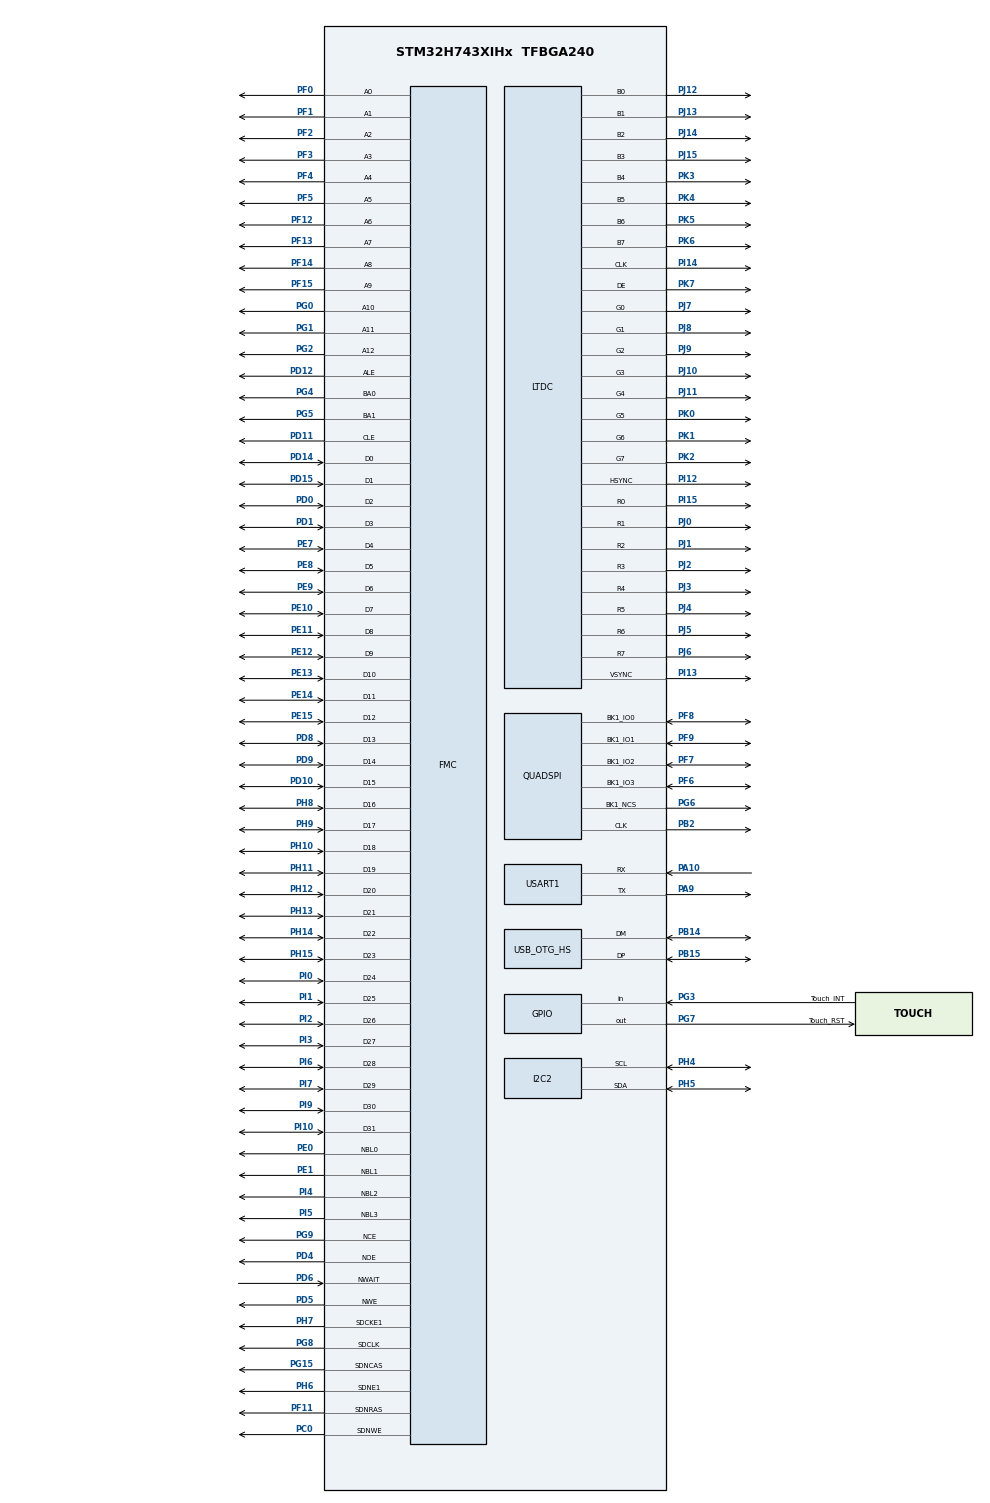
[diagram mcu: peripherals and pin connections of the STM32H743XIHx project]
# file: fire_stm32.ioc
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CORTEX_M7.AccessPermission-Cortex_Memory_Protection_Unit_Region1_Settings=MPU_REGION_PRIV_RW
CORTEX_M7.BaseAddress-Cortex_Memory_Protection_Unit_Region1_Settings=0xD0000000
CORTEX_M7.CPU_DCache=Enabled
CORTEX_M7.CPU_ICache=Enabled
CORTEX_M7.DisableExec-Cortex_Memory_Protection_Unit_Region0_Settings=MPU_INSTRUCTION_ACCESS_DISABLE
CORTEX_M7.DisableExec-Cortex_Memory_Protection_Unit_Region1_Settings=MPU_INSTRUCTION_ACCESS_ENABLE
CORTEX_M7.Enable-Cortex_Memory_Protection_Unit_Region0_Settings=MPU_REGION_ENABLE
CORTEX_M7.Enable-Cortex_Memory_Protection_Unit_Region1_Settings=MPU_REGION_ENABLE
CORTEX_M7.IsBufferable-Cortex_Memory_Protection_Unit_Region1_Settings=MPU_ACCESS_BUFFERABLE
CORTEX_M7.IsCacheable-Cortex_Memory_Protection_Unit_Region1_Settings=MPU_ACCESS_CACHEABLE
CORTEX_M7.IsShareable-Cortex_Memory_Protection_Unit_Region0_Settings=MPU_ACCESS_SHAREABLE
CORTEX_M7.IsShareable-Cortex_Memory_Protection_Unit_Region1_Settings=MPU_ACCESS_NOT_SHAREABLE
CORTEX_M7.AccessPermission-Cortex_Memory_Protection_Unit_Region2_Settings=MPU_REGION_FULL_ACCESS
CORTEX_M7.BaseAddress-Cortex_Memory_Protection_Unit_Region2_Settings=0x80000000
CORTEX_M7.DisableExec-Cortex_Memory_Protection_Unit_Region2_Settings=MPU_INSTRUCTION_ACCESS_DISABLE
CORTEX_M7.Enable-Cortex_Memory_Protection_Unit_Region2_Settings=MPU_REGION_ENABLE
CORTEX_M7.IsBufferable-Cortex_Memory_Protection_Unit_Region2_Settings=MPU_ACCESS_NOT_BUFFERABLE
CORTEX_M7.IsCacheable-Cortex_Memory_Protection_Unit_Region2_Settings=MPU_ACCESS_NOT_CACHEABLE
CORTEX_M7.IsShareable-Cortex_Memory_Protection_Unit_Region2_Settings=MPU_ACCESS_NOT_SHAREABLE
CORTEX_M7.Size-Cortex_Memory_Protection_Unit_Region2_Settings=MPU_REGION_SIZE_256MB
CORTEX_M7.SubRegionDisable-Cortex_Memory_Protection_Unit_Region2_Settings=0x00
CORTEX_M7.TypeExtField-Cortex_Memory_Protection_Unit_Region2_Settings=MPU_TEX_LEVEL0
CORTEX_M7.MPU_Control=MPU_PRIVILEGED_DEFAULT
CORTEX_M7.Size-Cortex_Memory_Protection_Unit_Region0_Settings=MPU_REGION_SIZE_4GB
CORTEX_M7.Size-Cortex_Memory_Protection_Unit_Region1_Settings=MPU_REGION_SIZE_64MB
CORTEX_M7.SubRegionDisable-Cortex_Memory_Protection_Unit_Region0_Settings=0x87
CORTEX_M7.TypeExtField-Cortex_Memory_Protection_Unit_Region1_Settings=MPU_TEX_LEVEL1
FMC.AttributeSpaceHiZSetupTime1=6
FMC.AttributeSpaceHoldSetupTime1=2
FMC.AttributeSpaceSetupTime1=2
FMC.AttributeSpaceWaitSetupTime1=6
FMC.CASLatency2=FMC_SDRAM_CAS_LATENCY_3
FMC.ColumnBitsNumber2=FMC_SDRAM_COLUMN_BITS_NUM_9
FMC.CommonSpaceHiZSetupTime1=6
FMC.CommonSpaceHoldSetupTime1=2
FMC.CommonSpaceSetupTime1=2
FMC.CommonSpaceWaitSetupTime1=6
FMC.EccComputation1=FMC_NAND_ECC_DISABLE
FMC.ExitSelfRefreshDelay2=8
FMC.LoadToActiveDelay2=2
FMC.NandBlockNbr1=1024
FMC.NandBlockSize1=64
FMC.NandExtraCommandEnable1=ENABLE
FMC.NandPageSize1=2048
FMC.NandPlaneNbr1=1
FMC.NandPlaneSize1=1024
FMC.NandSpareAreaSize1=64
FMC.RCDDelay2=2
FMC.RPDelay2=2
FMC.ReadBurst2=FMC_SDRAM_RBURST_ENABLE
FMC.ReadPipeDelay2=FMC_SDRAM_RPIPE_DELAY_1
FMC.RowBitsNumber2=FMC_SDRAM_ROW_BITS_NUM_13
FMC.RowCycleDelay2=8
FMC.SDBank2=FMC_SDRAM_BANK2
FMC.SDClockPeriod2=FMC_SDRAM_CLOCK_PERIOD_2
FMC.SelfRefreshTime2=5
FMC.TARSetupTime1=2
FMC.TCLRSetupTime1=2
FMC.WriteProtection2=FMC_SDRAM_WRITE_PROTECTION_DISABLE
FMC.WriteRecoveryTime2=4
FREERTOS.Tasks01=defaultTask,24,4096,StartDefaultTask,Default,NULL,Dynamic,NULL,NULL
FREERTOS.configENABLE_FPU=1
I2C2.Timing=0x90913232
LTDC.ActiveW=800
LTDC.HBP=46
LTDC.HFP=40
LTDC.HSync=1
LTDC.PCPolarity=LTDC_PCPOLARITY_IPC
LTDC.VBP=23
LTDC.VFP=13
LTDC.VSync=3
Mcu.Family=STM32H7
Mcu.Name=STM32H743XIHx
Mcu.Package=TFBGA240
NVIC.OTG_HS_IRQn=true\:5\:0\:false\:false\:true\:true\:true\:true\:true
NVIC.PriorityGroup=NVIC_PRIORITYGROUP_4
NVIC.TIM5_IRQn=true\:15\:0\:false\:false\:true\:false\:false\:true\:true
NVIC.TimeBase=TIM5_IRQn
NVIC.TimeBaseIP=TIM5
PA10.Mode=Asynchronous
PA10.Signal=USART1_RX
PA13\ (JTMS/SWDIO).Mode=Serial_Wire
PA13\ (JTMS/SWDIO).Signal=DEBUG_JTMS-SWDIO
PA14\ (JTCK/SWCLK).Mode=Serial_Wire
PA14\ (JTCK/SWCLK).Signal=DEBUG_JTCK-SWCLK
PA9.Mode=Asynchronous
PA9.Signal=USART1_TX
PB14.Mode=Device_Only_FS
PB14.Signal=USB_OTG_HS_DM
PB15.Mode=Device_Only_FS
PB15.Signal=USB_OTG_HS_DP
PB2.Mode=Single Bank 1
PB2.Signal=QUADSPI_CLK
PC0.Signal=FMC_SDNWE
PG3.GPIO_Label=Touch_INT
PG3.Signal=GPIO_Input
PG7.GPIO_Label=Touch_RST
PG7.GPIO_PinState=GPIO_PIN_RESET
PG7.GPIO_PuPd=GPIO_PULLDOWN
PG7.Signal=GPIO_Output
PD0.Signal=FMC_D2_DA2
PD1.Signal=FMC_D3_DA3
PD10.Signal=FMC_D15_DA15
PD11.Signal=FMC_A16_CLE
PD12.Signal=FMC_A17_ALE
PD14.Signal=FMC_D0_DA0
PD15.Signal=FMC_D1_DA1
PD4.Signal=FMC_NOE
PD5.Signal=FMC_NWE
PD6.Signal=FMC_NWAIT
PD8.Signal=FMC_D13_DA13
PD9.Signal=FMC_D14_DA14
PE0.Signal=FMC_NBL0
PE1.Signal=FMC_NBL1
PE10.Signal=FMC_D7_DA7
PE11.Signal=FMC_D8_DA8
PE12.Signal=FMC_D9_DA9
PE13.Signal=FMC_D10_DA10
PE14.Signal=FMC_D11_DA11
PE15.Signal=FMC_D12_DA12
PE7.Signal=FMC_D4_DA4
PE8.Signal=FMC_D5_DA5
PE9.Signal=FMC_D6_DA6
PF0.Signal=FMC_A0
PF1.Signal=FMC_A1
PF11.Signal=FMC_SDNRAS
PF12.Signal=FMC_A6
PF13.Signal=FMC_A7
PF14.Signal=FMC_A8
PF15.Signal=FMC_A9
PF2.Signal=FMC_A2
PF3.Signal=FMC_A3
PF4.Signal=FMC_A4
PF5.Signal=FMC_A5
PF6.Mode=Single Bank 1
PF6.Signal=QUADSPI_BK1_IO3
PF7.Mode=Single Bank 1
PF7.Signal=QUADSPI_BK1_IO2
PF8.Mode=Single Bank 1
PF8.Signal=QUADSPI_BK1_IO0
PF9.Mode=Single Bank 1
PF9.Signal=QUADSPI_BK1_IO1
PG0.Signal=FMC_A10
PG1.Signal=FMC_A11
PG15.Signal=FMC_SDNCAS
PG2.Signal=FMC_A12
PG4.Signal=FMC_A14_BA0
PG5.Signal=FMC_A15_BA1
PG6.Mode=Single Bank 1
PG6.Signal=QUADSPI_BK1_NCS
PG8.Signal=FMC_SDCLK
PG9.Mode=NandChipSelect3_1
PG9.Signal=FMC_NCE
PH0-OSC_IN\ (PH0).Mode=HSE-External-Oscillator
PH0-OSC_IN\ (PH0).Signal=RCC_OSC_IN
PH1-OSC_OUT\ (PH1).Mode=HSE-External-Oscillator
PH1-OSC_OUT\ (PH1).Signal=RCC_OSC_OUT
PH10.Signal=FMC_D18
PH4.Mode=I2C
PH4.Signal=I2C2_SCL
PH5.Mode=I2C
PH5.Signal=I2C2_SDA
PH11.Signal=FMC_D19
PH12.Signal=FMC_D20
PH13.Signal=FMC_D21
PH14.Signal=FMC_D22
PH15.Signal=FMC_D23
PH6.Mode=SdramChipSelect2_2
PH6.Signal=FMC_SDNE1
PH7.Mode=SdramChipSelect2_2
PH7.Signal=FMC_SDCKE1
PH8.Signal=FMC_D16
PH9.Signal=FMC_D17
PI0.Signal=FMC_D24
PI1.Signal=FMC_D25
PI10.Signal=FMC_D31
PI12.Mode=RGB888
PI12.Signal=LTDC_HSYNC
PI13.Mode=RGB888
PI13.Signal=LTDC_VSYNC
PI14.Mode=RGB888
PI14.Signal=LTDC_CLK
PI15.Mode=RGB888
PI15.Signal=LTDC_R0
PI2.Signal=FMC_D26
PI3.Signal=FMC_D27
PI4.Signal=FMC_NBL2
PI5.Signal=FMC_NBL3
PI6.Signal=FMC_D28
PI7.Signal=FMC_D29
PI9.Signal=FMC_D30
PJ0.Mode=RGB888
PJ0.Signal=LTDC_R1
PJ1.Mode=RGB888
PJ1.Signal=LTDC_R2
PJ10.Mode=RGB888
PJ10.Signal=LTDC_G3
PJ11.Mode=RGB888
PJ11.Signal=LTDC_G4
PJ12.Mode=RGB888
PJ12.Signal=LTDC_B0
PJ13.Mode=RGB888
PJ13.Signal=LTDC_B1
PJ14.Mode=RGB888
PJ14.Signal=LTDC_B2
PJ15.Mode=RGB888
PJ15.Signal=LTDC_B3
PJ2.Mode=RGB888
PJ2.Signal=LTDC_R3
PJ3.Mode=RGB888
PJ3.Signal=LTDC_R4
PJ4.Mode=RGB888
PJ4.Signal=LTDC_R5
PJ5.Mode=RGB888
PJ5.Signal=LTDC_R6
PJ6.Mode=RGB888
PJ6.Signal=LTDC_R7
PJ7.Mode=RGB888
PJ7.Signal=LTDC_G0
PJ8.Mode=RGB888
PJ8.Signal=LTDC_G1
PJ9.Mode=RGB888
PJ9.Signal=LTDC_G2
PK0.Mode=RGB888
PK0.Signal=LTDC_G5
PK1.Mode=RGB888
PK1.Signal=LTDC_G6
PK2.Mode=RGB888
PK2.Signal=LTDC_G7
PK3.Mode=RGB888
PK3.Signal=LTDC_B4
PK4.Mode=RGB888
PK4.Signal=LTDC_B5
PK5.Mode=RGB888
PK5.Signal=LTDC_B6
PK6.Mode=RGB888
PK6.Signal=LTDC_B7
PK7.Mode=RGB888
PK7.Signal=LTDC_DE
ProjectManager.HeapSize=0x200
ProjectManager.StackSize=0x400
ProjectManager.TargetToolchain=CMake
QUADSPI.ChipSelectHighTime=QSPI_CS_HIGH_TIME_5_CYCLE
QUADSPI.ClockMode=QSPI_CLOCK_MODE_0
QUADSPI.ClockPrescaler=1
QUADSPI.DualFlash=QSPI_DUALFLASH_DISABLE
QUADSPI.FifoThreshold=4
QUADSPI.FlashID=QSPI_FLASH_ID_1
QUADSPI.FlashSize=24
QUADSPI.SampleShifting=QSPI_SAMPLE_SHIFTING_HALFCYCLE
RCC.ADCFreq_Value=50390625
RCC.APB1Freq_Value=120000000
RCC.APB2Freq_Value=120000000
RCC.APB3Freq_Value=120000000
RCC.APB4Freq_Value=120000000
RCC.CortexFreq_Value=480000000
RCC.D1PPRE=RCC_APB3_DIV2
RCC.D2PPRE1=RCC_APB1_DIV2
RCC.D2PPRE2=RCC_APB2_DIV2
RCC.D3PPRE=RCC_APB4_DIV2
RCC.DIVM1=5
RCC.DIVM3=25
RCC.DIVN1=192
RCC.DIVN3=386
RCC.DIVQ1=20
RCC.DIVQ3=8
RCC.DIVR3=14
RCC.EnableCSSLSE=false
RCC.EnbaleCSS=true
RCC.HCLKFreq_Value=240000000
RCC.HPRE=RCC_HCLK_DIV2
RCC.LockedElements=USBoutput,CpuClockOutput
RCC.PLL3FRACN=5710
RCC.PLLFRACN=0
RCC.PLLSourceVirtual=RCC_PLLSOURCE_HSE
RCC.RTCClockSelection=RCC_RTCCLKSOURCE_LSI
RCC.SYSCLKFreq_VALUE=480000000
RCC.SYSCLKSource=RCC_SYSCLKSOURCE_PLLCLK
RCC.USBCLockSelection=RCC_USBCLKSOURCE_PLL
RCC.USBFreq_Value=48000000
SH.FMC_A0.0=FMC_A0,13b-sda2
SH.FMC_A1.0=FMC_A1,13b-sda2
SH.FMC_A10.0=FMC_A10,13b-sda2
SH.FMC_A11.0=FMC_A11,13b-sda2
SH.FMC_A12.0=FMC_A12,13b-sda2
SH.FMC_A14_BA0.0=FMC_BA0,FourSdramBanks2
SH.FMC_A15_BA1.0=FMC_BA1,FourSdramBanks2
SH.FMC_A16_CLE.0=FMC_CLE,8b-dmux1
SH.FMC_A17_ALE.0=FMC_ALE,8b-dmux1
SH.FMC_A2.0=FMC_A2,13b-sda2
SH.FMC_A3.0=FMC_A3,13b-sda2
SH.FMC_A4.0=FMC_A4,13b-sda2
SH.FMC_A5.0=FMC_A5,13b-sda2
SH.FMC_A6.0=FMC_A6,13b-sda2
SH.FMC_A7.0=FMC_A7,13b-sda2
SH.FMC_A8.0=FMC_A8,13b-sda2
SH.FMC_A9.0=FMC_A9,13b-sda2
SH.FMC_D0_DA0.0=FMC_D0,sd-32b-d2
SH.FMC_D0_DA0.1=FMC_D0,8b-dmux1
SH.FMC_D10_DA10.0=FMC_D10,sd-32b-d2
SH.FMC_D11_DA11.0=FMC_D11,sd-32b-d2
SH.FMC_D12_DA12.0=FMC_D12,sd-32b-d2
SH.FMC_D13_DA13.0=FMC_D13,sd-32b-d2
SH.FMC_D14_DA14.0=FMC_D14,sd-32b-d2
SH.FMC_D15_DA15.0=FMC_D15,sd-32b-d2
SH.FMC_D16.0=FMC_D16,sd-32b-d2
SH.FMC_D17.0=FMC_D17,sd-32b-d2
SH.FMC_D18.0=FMC_D18,sd-32b-d2
SH.FMC_D19.0=FMC_D19,sd-32b-d2
SH.FMC_D1_DA1.0=FMC_D1,sd-32b-d2
SH.FMC_D1_DA1.1=FMC_D1,8b-dmux1
SH.FMC_D20.0=FMC_D20,sd-32b-d2
SH.FMC_D21.0=FMC_D21,sd-32b-d2
SH.FMC_D22.0=FMC_D22,sd-32b-d2
SH.FMC_D23.0=FMC_D23,sd-32b-d2
SH.FMC_D24.0=FMC_D24,sd-32b-d2
SH.FMC_D25.0=FMC_D25,sd-32b-d2
SH.FMC_D26.0=FMC_D26,sd-32b-d2
SH.FMC_D27.0=FMC_D27,sd-32b-d2
SH.FMC_D28.0=FMC_D28,sd-32b-d2
SH.FMC_D29.0=FMC_D29,sd-32b-d2
SH.FMC_D2_DA2.0=FMC_D2,sd-32b-d2
SH.FMC_D2_DA2.1=FMC_D2,8b-dmux1
SH.FMC_D30.0=FMC_D30,sd-32b-d2
SH.FMC_D31.0=FMC_D31,sd-32b-d2
SH.FMC_D3_DA3.0=FMC_D3,sd-32b-d2
SH.FMC_D3_DA3.1=FMC_D3,8b-dmux1
SH.FMC_D4_DA4.0=FMC_D4,sd-32b-d2
SH.FMC_D4_DA4.1=FMC_D4,8b-dmux1
SH.FMC_D5_DA5.0=FMC_D5,sd-32b-d2
SH.FMC_D5_DA5.1=FMC_D5,8b-dmux1
SH.FMC_D6_DA6.0=FMC_D6,sd-32b-d2
SH.FMC_D6_DA6.1=FMC_D6,8b-dmux1
SH.FMC_D7_DA7.0=FMC_D7,sd-32b-d2
SH.FMC_D7_DA7.1=FMC_D7,8b-dmux1
SH.FMC_D8_DA8.0=FMC_D8,sd-32b-d2
SH.FMC_D9_DA9.0=FMC_D9,sd-32b-d2
SH.FMC_NBL0.0=FMC_NBL0,Sd4ByteEnable2
SH.FMC_NBL1.0=FMC_NBL1,Sd4ByteEnable2
SH.FMC_NBL2.0=FMC_NBL2,Sd4ByteEnable2
SH.FMC_NBL3.0=FMC_NBL3,Sd4ByteEnable2
SH.FMC_NOE.0=FMC_NOE,8b-dmux1
SH.FMC_NWAIT.0=FMC_NWAIT,Wait1
SH.FMC_NWE.0=FMC_NWE,8b-dmux1
SH.FMC_SDCLK.0=FMC_SDCLK,13b-sda2
SH.FMC_SDNCAS.0=FMC_SDNCAS,13b-sda2
SH.FMC_SDNRAS.0=FMC_SDNRAS,13b-sda2
SH.FMC_SDNWE.0=FMC_SDNWE,13b-sda2
USART1.VirtualMode-Asynchronous=VM_ASYNC
USB_OTG_HS.VirtualMode-Device_Only_FS=Device_Only_FS
VP_DMA2D_VS_DMA2D.Mode=DMA2D_Activate
VP_FREERTOS_VS_CMSIS_V2.Mode=CMSIS_V2
VP_LIBJPEG_VS_JPEGLIB.Mode=Enabled
VP_MEMORYMAP_VS_MEMORYMAP.Mode=CurAppReg
VP_RNG_VS_RNG.Mode=RNG_Activate
VP_RTC_VS_RTC_Activate.Mode=RTC_Enabled
VP_SYS_VS_tim5.Mode=TIM5
board=custom

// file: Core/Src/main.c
/* USER CODE BEGIN Header */
/**
  ******************************************************************************
  * @file           : main.c
  * @brief          : Main program body
  ******************************************************************************
  * @attention
  *
  * Copyright (c) 2026 STMicroelectronics.
  * All rights reserved.
  *
  * This software is licensed under terms that can be found in the LICENSE file
  * in the root directory of this software component.
  * If no LICENSE file comes with this software, it is provided AS-IS.
  *
  ******************************************************************************
  */
/* USER CODE END Header */
#include "main.h"
#include "FreeRTOS.h"
#include "cmsis_os2.h"
#include "libjpeg.h"

/* USER CODE BEGIN Includes */
#include "lvgl.h"
#include "lvgl/drivers/display/lv_st_ltdc.h"
#include "demos/lv_demos.h"
#include "yaffs_osglue.h"
#include "touch.h"
#include "task.h"
/* USER CODE END Includes */

/* USER CODE BEGIN PD */
/* Framebuffers in SDRAM, RGB565 800x480 */
#define FB_ADDR1  0xD0000000
#define FB_ADDR2  (FB_ADDR1 + 800 * 480 * 2)
/* USER CODE END PD */

DMA2D_HandleTypeDef hdma2d;

I2C_HandleTypeDef hi2c2;

LTDC_HandleTypeDef hltdc;

QSPI_HandleTypeDef hqspi;

RNG_HandleTypeDef hrng;

RTC_HandleTypeDef hrtc;

UART_HandleTypeDef huart1;

PCD_HandleTypeDef hpcd_USB_OTG_HS;

NAND_HandleTypeDef hnand1;
SDRAM_HandleTypeDef hsdram2;

/* Definitions for defaultTask */
osThreadId_t defaultTaskHandle;
const osThreadAttr_t defaultTask_attributes = {
  .name = "defaultTask",
  .stack_size = 6144 * 4,
  .priority = (osPriority_t) osPriorityNormal,
};
/* USER CODE BEGIN PV */
/* FreeRTOS heap must live in RAM_D2 (DTCMRAM is too small); heap_4 does not
   require zero-initialized memory, so a NOLOAD custom section is fine. */
__attribute__((section(".ram_d2_heap")))
uint8_t ucHeap[configTOTAL_HEAP_SIZE];

osThreadId_t mountTaskHandle;
const osThreadAttr_t mountTask_attributes = {
  .name = "mountTask",
  .stack_size = 2048 * 4,
  .priority = (osPriority_t) osPriorityBelowNormal,
};
/* USER CODE END PV */

void SystemClock_Config(void);
void PeriphCommonClock_Config(void);
static void MPU_Config(void);
static void MX_GPIO_Init(void);
static void MX_FMC_Init(void);
static void MX_QUADSPI_Init(void);
static void MX_USART1_UART_Init(void);
static void MX_I2C2_Init(void);
static void MX_DMA2D_Init(void);
static void MX_RNG_Init(void);
static void MX_RTC_Init(void);
static void MX_USB_OTG_HS_PCD_Init(void);
static void MX_LTDC_Init(void);
void StartDefaultTask(void *argument);

/* USER CODE BEGIN PFP */
void StartMountTask(void *argument);
/* USER CODE END PFP */

int main(void)
{

  /* USER CODE BEGIN 1 */
  /* FMC NAND mapped at 0x80000000 must be Device/non-cacheable. Configured
     here instead of inside MPU_Config() because CubeMX regenerates that whole
     function; region registers persist, so MPU_Config() re-enabling the MPU
     keeps this setting. */
  {
    MPU_Region_InitTypeDef nand_region = {0};
    HAL_MPU_Disable();
    nand_region.Enable = MPU_REGION_ENABLE;
    nand_region.Number = MPU_REGION_NUMBER2;
    nand_region.BaseAddress = 0x80000000;
    nand_region.Size = MPU_REGION_SIZE_256MB;
    nand_region.SubRegionDisable = 0x00;
    nand_region.TypeExtField = MPU_TEX_LEVEL0;
    nand_region.AccessPermission = MPU_REGION_FULL_ACCESS;
    nand_region.DisableExec = MPU_INSTRUCTION_ACCESS_DISABLE;
    nand_region.IsShareable = MPU_ACCESS_NOT_SHAREABLE;
    nand_region.IsCacheable = MPU_ACCESS_NOT_CACHEABLE;
    nand_region.IsBufferable = MPU_ACCESS_NOT_BUFFERABLE;
    HAL_MPU_ConfigRegion(&nand_region);
  }
  /* USER CODE END 1 */

  /* MPU Configuration--------------------------------------------------------*/
  MPU_Config();

  /* Enable the CPU Cache */

  /* Enable I-Cache---------------------------------------------------------*/
  SCB_EnableICache();

  /* Enable D-Cache---------------------------------------------------------*/
  SCB_EnableDCache();

  /* MCU Configuration--------------------------------------------------------*/

  /* Reset of all peripherals, Initializes the Flash interface and the Systick. */
  HAL_Init();

  /* Configure the system clock */
  SystemClock_Config();

  /* Configure the peripherals common clocks */
  PeriphCommonClock_Config();

  /* USER CODE BEGIN SysInit */
  /* RAM_D2 hosts the FreeRTOS heap (.ram_d2_heap) */
  __HAL_RCC_D2SRAM1_CLK_ENABLE();
  __HAL_RCC_D2SRAM2_CLK_ENABLE();
  __HAL_RCC_D2SRAM3_CLK_ENABLE();
  /* USER CODE END SysInit */

  /* Initialize all configured peripherals */
  MX_GPIO_Init();
  MX_FMC_Init();
  MX_QUADSPI_Init();
  MX_USART1_UART_Init();
  MX_I2C2_Init();
  MX_DMA2D_Init();
  MX_RNG_Init();
  MX_RTC_Init();
  MX_LIBJPEG_Init();
  MX_USB_OTG_HS_PCD_Init();
  MX_LTDC_Init();
  /* USER CODE BEGIN 2 */
  /* LCD backlight: PD13, stays OFF until the first LVGL frame is rendered */
  __HAL_RCC_GPIOD_CLK_ENABLE();
  GPIO_InitTypeDef gpio = {0};
  gpio.Pin = GPIO_PIN_13;
  gpio.Mode = GPIO_MODE_OUTPUT_PP;
  gpio.Pull = GPIO_NOPULL;
  gpio.Speed = GPIO_SPEED_FREQ_LOW;
  HAL_GPIO_Init(GPIOD, &gpio);
  HAL_GPIO_WritePin(GPIOD, GPIO_PIN_13, GPIO_PIN_RESET);
  /* USER CODE END 2 */

  /* Init scheduler */
  osKernelInitialize();

  /* Create the thread(s) */
  /* creation of defaultTask */
  defaultTaskHandle = osThreadNew(StartDefaultTask, NULL, &defaultTask_attributes);

  /* USER CODE BEGIN RTOS_THREADS */
  mountTaskHandle = osThreadNew(StartMountTask, NULL, &mountTask_attributes);
  /* USER CODE END RTOS_THREADS */

  /* Start scheduler */
  osKernelStart();

  /* We should never get here as control is now taken by the scheduler */

  /* Infinite loop */
  while (1)
  {

  }
}

void SystemClock_Config(void)
{
  RCC_OscInitTypeDef RCC_OscInitStruct = {0};
  RCC_ClkInitTypeDef RCC_ClkInitStruct = {0};

  /** Supply configuration update enable
  */
  HAL_PWREx_ConfigSupply(PWR_LDO_SUPPLY);

  /** Configure the main internal regulator output voltage
  */
  __HAL_PWR_VOLTAGESCALING_CONFIG(PWR_REGULATOR_VOLTAGE_SCALE0);

  while(!__HAL_PWR_GET_FLAG(PWR_FLAG_VOSRDY)) {}

  /* RTC runs from LSI: no 32.768kHz crystal is fitted on this board, and
     waiting on LSE here would fail into Error_Handler() before any display
     init runs. */
  HAL_PWR_EnableBkUpAccess();

  /** Initializes the RCC Oscillators according to the specified parameters
  * in the RCC_OscInitTypeDef structure.
  */
  RCC_OscInitStruct.OscillatorType = RCC_OSCILLATORTYPE_HSI48|RCC_OSCILLATORTYPE_LSI
                              |RCC_OSCILLATORTYPE_HSE;
  RCC_OscInitStruct.HSEState = RCC_HSE_ON;
  RCC_OscInitStruct.LSIState = RCC_LSI_ON;
  RCC_OscInitStruct.HSI48State = RCC_HSI48_ON;
  RCC_OscInitStruct.PLL.PLLState = RCC_PLL_ON;
  RCC_OscInitStruct.PLL.PLLSource = RCC_PLLSOURCE_HSE;
  RCC_OscInitStruct.PLL.PLLM = 5;
  RCC_OscInitStruct.PLL.PLLN = 192;
  RCC_OscInitStruct.PLL.PLLP = 2;
  RCC_OscInitStruct.PLL.PLLQ = 20;
  RCC_OscInitStruct.PLL.PLLR = 2;
  RCC_OscInitStruct.PLL.PLLRGE = RCC_PLL1VCIRANGE_2;
  RCC_OscInitStruct.PLL.PLLVCOSEL = RCC_PLL1VCOWIDE;
  RCC_OscInitStruct.PLL.PLLFRACN = 0;
  if (HAL_RCC_OscConfig(&RCC_OscInitStruct) != HAL_OK)
  {
    Error_Handler();
  }

  /** Initializes the CPU, AHB and APB buses clocks
  */
  RCC_ClkInitStruct.ClockType = RCC_CLOCKTYPE_HCLK|RCC_CLOCKTYPE_SYSCLK
                              |RCC_CLOCKTYPE_PCLK1|RCC_CLOCKTYPE_PCLK2
                              |RCC_CLOCKTYPE_D3PCLK1|RCC_CLOCKTYPE_D1PCLK1;
  RCC_ClkInitStruct.SYSCLKSource = RCC_SYSCLKSOURCE_PLLCLK;
  RCC_ClkInitStruct.SYSCLKDivider = RCC_SYSCLK_DIV1;
  RCC_ClkInitStruct.AHBCLKDivider = RCC_HCLK_DIV2;
  RCC_ClkInitStruct.APB3CLKDivider = RCC_APB3_DIV2;
  RCC_ClkInitStruct.APB1CLKDivider = RCC_APB1_DIV2;
  RCC_ClkInitStruct.APB2CLKDivider = RCC_APB2_DIV2;
  RCC_ClkInitStruct.APB4CLKDivider = RCC_APB4_DIV2;

  if (HAL_RCC_ClockConfig(&RCC_ClkInitStruct, FLASH_LATENCY_4) != HAL_OK)
  {
    Error_Handler();
  }

  /** Enables the Clock Security System
  */
  HAL_RCC_EnableCSS();
}

void PeriphCommonClock_Config(void)
{
  RCC_PeriphCLKInitTypeDef PeriphClkInitStruct = {0};

  /** Initializes the peripherals clock
  */
  PeriphClkInitStruct.PeriphClockSelection = RCC_PERIPHCLK_USB|RCC_PERIPHCLK_LTDC;
  /* LTDC pixel clock for 60Hz: (386 + 5710/8192)MHz / 14 = 27.6212MHz;
     27.6212MHz / (887 * 519) = 60.00Hz */
  PeriphClkInitStruct.PLL3.PLL3M = 25;
  PeriphClkInitStruct.PLL3.PLL3N = 386;
  PeriphClkInitStruct.PLL3.PLL3P = 2;
  PeriphClkInitStruct.PLL3.PLL3Q = 8;
  PeriphClkInitStruct.PLL3.PLL3R = 14;
  PeriphClkInitStruct.PLL3.PLL3RGE = RCC_PLL3VCIRANGE_0;
  PeriphClkInitStruct.PLL3.PLL3VCOSEL = RCC_PLL3VCOWIDE;
  PeriphClkInitStruct.PLL3.PLL3FRACN = 5710;
  /* USB now from PLL1Q (48MHz exact); PLL3 VCO is no longer 384MHz */
  PeriphClkInitStruct.UsbClockSelection = RCC_USBCLKSOURCE_PLL;
  if (HAL_RCCEx_PeriphCLKConfig(&PeriphClkInitStruct) != HAL_OK)
  {
    Error_Handler();
  }
}

static void MX_DMA2D_Init(void)
{

  hdma2d.Instance = DMA2D;
  hdma2d.Init.Mode = DMA2D_M2M;
  hdma2d.Init.ColorMode = DMA2D_OUTPUT_ARGB8888;
  hdma2d.Init.OutputOffset = 0;
  hdma2d.LayerCfg[1].InputOffset = 0;
  hdma2d.LayerCfg[1].InputColorMode = DMA2D_INPUT_ARGB8888;
  hdma2d.LayerCfg[1].AlphaMode = DMA2D_NO_MODIF_ALPHA;
  hdma2d.LayerCfg[1].InputAlpha = 0;
  hdma2d.LayerCfg[1].AlphaInverted = DMA2D_REGULAR_ALPHA;
  hdma2d.LayerCfg[1].RedBlueSwap = DMA2D_RB_REGULAR;
  hdma2d.LayerCfg[1].ChromaSubSampling = DMA2D_NO_CSS;
  if (HAL_DMA2D_Init(&hdma2d) != HAL_OK)
  {
    Error_Handler();
  }
  if (HAL_DMA2D_ConfigLayer(&hdma2d, 1) != HAL_OK)
  {
    Error_Handler();
  }
  /* USER CODE BEGIN DMA2D_Init 2 */
  HAL_NVIC_SetPriority(DMA2D_IRQn, 6, 0);
  HAL_NVIC_EnableIRQ(DMA2D_IRQn);
  /* USER CODE END DMA2D_Init 2 */

}

static void MX_I2C2_Init(void)
{

  hi2c2.Instance = I2C2;
  hi2c2.Init.Timing = 0x90913232;
  hi2c2.Init.OwnAddress1 = 0;
  hi2c2.Init.AddressingMode = I2C_ADDRESSINGMODE_7BIT;
  hi2c2.Init.DualAddressMode = I2C_DUALADDRESS_DISABLE;
  hi2c2.Init.OwnAddress2 = 0;
  hi2c2.Init.OwnAddress2Masks = I2C_OA2_NOMASK;
  hi2c2.Init.GeneralCallMode = I2C_GENERALCALL_DISABLE;
  hi2c2.Init.NoStretchMode = I2C_NOSTRETCH_DISABLE;
  if (HAL_I2C_Init(&hi2c2) != HAL_OK)
  {
    Error_Handler();
  }

  /** Configure Analogue filter
  */
  if (HAL_I2CEx_ConfigAnalogFilter(&hi2c2, I2C_ANALOGFILTER_ENABLE) != HAL_OK)
  {
    Error_Handler();
  }

  /** Configure Digital filter
  */
  if (HAL_I2CEx_ConfigDigitalFilter(&hi2c2, 0) != HAL_OK)
  {
    Error_Handler();
  }

}

static void MX_LTDC_Init(void)
{

  LTDC_LayerCfgTypeDef pLayerCfg = {0};
  LTDC_LayerCfgTypeDef pLayerCfg1 = {0};

  hltdc.Instance = LTDC;
  hltdc.Init.HSPolarity = LTDC_HSPOLARITY_AL;
  hltdc.Init.VSPolarity = LTDC_VSPOLARITY_AL;
  hltdc.Init.DEPolarity = LTDC_DEPOLARITY_AL;
  hltdc.Init.PCPolarity = LTDC_PCPOLARITY_IPC;
  hltdc.Init.HorizontalSync = 0;
  hltdc.Init.VerticalSync = 2;
  hltdc.Init.AccumulatedHBP = 46;
  hltdc.Init.AccumulatedVBP = 25;
  hltdc.Init.AccumulatedActiveW = 846;
  hltdc.Init.AccumulatedActiveH = 505;
  hltdc.Init.TotalWidth = 886;
  hltdc.Init.TotalHeigh = 518;
  hltdc.Init.Backcolor.Blue = 0;
  hltdc.Init.Backcolor.Green = 0;
  hltdc.Init.Backcolor.Red = 0;
  if (HAL_LTDC_Init(&hltdc) != HAL_OK)
  {
    Error_Handler();
  }
  pLayerCfg.WindowX0 = 0;
  pLayerCfg.WindowX1 = 0;
  pLayerCfg.WindowY0 = 0;
  pLayerCfg.WindowY1 = 0;
  pLayerCfg.PixelFormat = LTDC_PIXEL_FORMAT_ARGB8888;
  pLayerCfg.Alpha = 0;
  pLayerCfg.Alpha0 = 0;
  pLayerCfg.BlendingFactor1 = LTDC_BLENDING_FACTOR1_CA;
  pLayerCfg.BlendingFactor2 = LTDC_BLENDING_FACTOR2_CA;
  pLayerCfg.FBStartAdress = 0;
  pLayerCfg.ImageWidth = 0;
  pLayerCfg.ImageHeight = 0;
  pLayerCfg.Backcolor.Blue = 0;
  pLayerCfg.Backcolor.Green = 0;
  pLayerCfg.Backcolor.Red = 0;
  if (HAL_LTDC_ConfigLayer(&hltdc, &pLayerCfg, 0) != HAL_OK)
  {
    Error_Handler();
  }
  pLayerCfg1.WindowX0 = 0;
  pLayerCfg1.WindowX1 = 0;
  pLayerCfg1.WindowY0 = 0;
  pLayerCfg1.WindowY1 = 0;
  pLayerCfg1.PixelFormat = LTDC_PIXEL_FORMAT_ARGB8888;
  pLayerCfg1.Alpha = 0;
  pLayerCfg1.Alpha0 = 0;
  pLayerCfg1.BlendingFactor1 = LTDC_BLENDING_FACTOR1_CA;
  pLayerCfg1.BlendingFactor2 = LTDC_BLENDING_FACTOR2_CA;
  pLayerCfg1.FBStartAdress = 0;
  pLayerCfg1.ImageWidth = 0;
  pLayerCfg1.ImageHeight = 0;
  pLayerCfg1.Backcolor.Blue = 0;
  pLayerCfg1.Backcolor.Green = 0;
  pLayerCfg1.Backcolor.Red = 0;
  if (HAL_LTDC_ConfigLayer(&hltdc, &pLayerCfg1, 1) != HAL_OK)
  {
    Error_Handler();
  }
  /* USER CODE BEGIN LTDC_Init 2 */
  /* Configure layer 0 for LVGL: 800x480 RGB565, framebuffer in SDRAM */
  hltdc.LayerCfg[0].WindowX0 = 0;
  hltdc.LayerCfg[0].WindowX1 = 800;
  hltdc.LayerCfg[0].WindowY0 = 0;
  hltdc.LayerCfg[0].WindowY1 = 480;
  hltdc.LayerCfg[0].PixelFormat = LTDC_PIXEL_FORMAT_RGB565;
  hltdc.LayerCfg[0].Alpha = 255;
  hltdc.LayerCfg[0].FBStartAdress = 0xD0000000;
  hltdc.LayerCfg[0].ImageWidth = 800;
  hltdc.LayerCfg[0].ImageHeight = 480;
  HAL_LTDC_ConfigLayer(&hltdc, &hltdc.LayerCfg[0], 0);
  /* The LVGL LTDC driver uses the register-reload interrupt to sync
     framebuffer swaps. Priority 6 is at or below the FreeRTOS max-syscall
     priority (5), which the ISR callbacks require. */
  HAL_NVIC_SetPriority(LTDC_IRQn, 6, 0);
  HAL_NVIC_EnableIRQ(LTDC_IRQn);
  /* USER CODE END LTDC_Init 2 */

}

static void MX_QUADSPI_Init(void)
{

  /* QUADSPI parameter configuration*/
  hqspi.Instance = QUADSPI;
  hqspi.Init.ClockPrescaler = 1;
  hqspi.Init.FifoThreshold = 4;
  hqspi.Init.SampleShifting = QSPI_SAMPLE_SHIFTING_HALFCYCLE;
  hqspi.Init.FlashSize = 24;
  hqspi.Init.ChipSelectHighTime = QSPI_CS_HIGH_TIME_5_CYCLE;
  hqspi.Init.ClockMode = QSPI_CLOCK_MODE_0;
  hqspi.Init.FlashID = QSPI_FLASH_ID_1;
  hqspi.Init.DualFlash = QSPI_DUALFLASH_DISABLE;
  if (HAL_QSPI_Init(&hqspi) != HAL_OK)
  {
    Error_Handler();
  }

}

static void MX_RNG_Init(void)
{

  hrng.Instance = RNG;
  hrng.Init.ClockErrorDetection = RNG_CED_ENABLE;
  if (HAL_RNG_Init(&hrng) != HAL_OK)
  {
    Error_Handler();
  }

}

static void MX_RTC_Init(void)
{

  /** Initialize RTC Only
  */
  hrtc.Instance = RTC;
  hrtc.Init.HourFormat = RTC_HOURFORMAT_24;
  hrtc.Init.AsynchPrediv = 127;
  hrtc.Init.SynchPrediv = 249;
  hrtc.Init.OutPut = RTC_OUTPUT_DISABLE;
  hrtc.Init.OutPutPolarity = RTC_OUTPUT_POLARITY_HIGH;
  hrtc.Init.OutPutType = RTC_OUTPUT_TYPE_OPENDRAIN;
  hrtc.Init.OutPutRemap = RTC_OUTPUT_REMAP_NONE;
  if (HAL_RTC_Init(&hrtc) != HAL_OK)
  {
    Error_Handler();
  }

}

static void MX_USART1_UART_Init(void)
{

  huart1.Instance = USART1;
  huart1.Init.BaudRate = 115200;
  huart1.Init.WordLength = UART_WORDLENGTH_8B;
  huart1.Init.StopBits = UART_STOPBITS_1;
  huart1.Init.Parity = UART_PARITY_NONE;
  huart1.Init.Mode = UART_MODE_TX_RX;
  huart1.Init.HwFlowCtl = UART_HWCONTROL_NONE;
  huart1.Init.OverSampling = UART_OVERSAMPLING_16;
  huart1.Init.OneBitSampling = UART_ONE_BIT_SAMPLE_DISABLE;
  huart1.Init.ClockPrescaler = UART_PRESCALER_DIV1;
  huart1.AdvancedInit.AdvFeatureInit = UART_ADVFEATURE_NO_INIT;
  if (HAL_UART_Init(&huart1) != HAL_OK)
  {
    Error_Handler();
  }
  if (HAL_UARTEx_SetTxFifoThreshold(&huart1, UART_TXFIFO_THRESHOLD_1_8) != HAL_OK)
  {
    Error_Handler();
  }
  if (HAL_UARTEx_SetRxFifoThreshold(&huart1, UART_RXFIFO_THRESHOLD_1_8) != HAL_OK)
  {
    Error_Handler();
  }
  if (HAL_UARTEx_DisableFifoMode(&huart1) != HAL_OK)
  {
    Error_Handler();
  }

}

static void MX_USB_OTG_HS_PCD_Init(void)
{

  hpcd_USB_OTG_HS.Instance = USB_OTG_HS;
  hpcd_USB_OTG_HS.Init.dev_endpoints = 9;
  hpcd_USB_OTG_HS.Init.speed = PCD_SPEED_FULL;
  hpcd_USB_OTG_HS.Init.dma_enable = DISABLE;
  hpcd_USB_OTG_HS.Init.phy_itface = USB_OTG_EMBEDDED_PHY;
  hpcd_USB_OTG_HS.Init.Sof_enable = DISABLE;
  hpcd_USB_OTG_HS.Init.low_power_enable = DISABLE;
  hpcd_USB_OTG_HS.Init.lpm_enable = DISABLE;
  hpcd_USB_OTG_HS.Init.vbus_sensing_enable = DISABLE;
  hpcd_USB_OTG_HS.Init.use_dedicated_ep1 = DISABLE;
  hpcd_USB_OTG_HS.Init.use_external_vbus = DISABLE;
  if (HAL_PCD_Init(&hpcd_USB_OTG_HS) != HAL_OK)
  {
    Error_Handler();
  }

}

/* FMC initialization function */
static void MX_FMC_Init(void)
{

  FMC_NAND_PCC_TimingTypeDef ComSpaceTiming = {0};
  FMC_NAND_PCC_TimingTypeDef AttSpaceTiming = {0};
  FMC_SDRAM_TimingTypeDef SdramTiming = {0};

  /** Perform the NAND1 memory initialization sequence
  */
  hnand1.Instance = FMC_NAND_DEVICE;
  /* hnand1.Init */
  hnand1.Init.NandBank = FMC_NAND_BANK3;
  hnand1.Init.Waitfeature = FMC_NAND_WAIT_FEATURE_ENABLE;
  hnand1.Init.MemoryDataWidth = FMC_NAND_MEM_BUS_WIDTH_8;
  hnand1.Init.EccComputation = FMC_NAND_ECC_DISABLE;
  hnand1.Init.ECCPageSize = FMC_NAND_ECC_PAGE_SIZE_256BYTE;
  hnand1.Init.TCLRSetupTime = 2;
  hnand1.Init.TARSetupTime = 2;
  /* hnand1.Config */
  hnand1.Config.PageSize = 2048;
  hnand1.Config.SpareAreaSize = 64;
  hnand1.Config.BlockSize = 64;
  hnand1.Config.BlockNbr = 1024;
  hnand1.Config.PlaneNbr = 1;
  hnand1.Config.PlaneSize = 1024;
  hnand1.Config.ExtraCommandEnable = ENABLE;
  /* ComSpaceTiming */
  ComSpaceTiming.SetupTime = 2;
  ComSpaceTiming.WaitSetupTime = 6;
  ComSpaceTiming.HoldSetupTime = 2;
  ComSpaceTiming.HiZSetupTime = 6;
  /* AttSpaceTiming */
  AttSpaceTiming.SetupTime = 2;
  AttSpaceTiming.WaitSetupTime = 6;
  AttSpaceTiming.HoldSetupTime = 2;
  AttSpaceTiming.HiZSetupTime = 6;

  if (HAL_NAND_Init(&hnand1, &ComSpaceTiming, &AttSpaceTiming) != HAL_OK)
  {
    Error_Handler( );
  }

  /** Perform the SDRAM2 memory initialization sequence
  */
  hsdram2.Instance = FMC_SDRAM_DEVICE;
  /* hsdram2.Init */
  hsdram2.Init.SDBank = FMC_SDRAM_BANK2;
  hsdram2.Init.ColumnBitsNumber = FMC_SDRAM_COLUMN_BITS_NUM_9;
  hsdram2.Init.RowBitsNumber = FMC_SDRAM_ROW_BITS_NUM_13;
  hsdram2.Init.MemoryDataWidth = FMC_SDRAM_MEM_BUS_WIDTH_32;
  hsdram2.Init.InternalBankNumber = FMC_SDRAM_INTERN_BANKS_NUM_4;
  hsdram2.Init.CASLatency = FMC_SDRAM_CAS_LATENCY_3;
  hsdram2.Init.WriteProtection = FMC_SDRAM_WRITE_PROTECTION_DISABLE;
  hsdram2.Init.SDClockPeriod = FMC_SDRAM_CLOCK_PERIOD_2;
  hsdram2.Init.ReadBurst = FMC_SDRAM_RBURST_ENABLE;
  hsdram2.Init.ReadPipeDelay = FMC_SDRAM_RPIPE_DELAY_1;
  /* SdramTiming */
  SdramTiming.LoadToActiveDelay = 2;
  SdramTiming.ExitSelfRefreshDelay = 8;
  SdramTiming.SelfRefreshTime = 5;
  SdramTiming.RowCycleDelay = 8;
  SdramTiming.WriteRecoveryTime = 4;
  SdramTiming.RPDelay = 2;
  SdramTiming.RCDDelay = 2;

  if (HAL_SDRAM_Init(&hsdram2, &SdramTiming) != HAL_OK)
  {
    Error_Handler( );
  }

  /* USER CODE BEGIN FMC_Init 2 */

  /* SDRAM initialization command sequence */
  FMC_SDRAM_CommandTypeDef cmd = {0};

  cmd.CommandMode  = FMC_SDRAM_CMD_CLK_ENABLE;
  cmd.CommandTarget = FMC_SDRAM_CMD_TARGET_BANK2;
  HAL_SDRAM_SendCommand(&hsdram2, &cmd, 0xFFFF);
  HAL_Delay(1);

  cmd.CommandMode  = FMC_SDRAM_CMD_PALL;
  cmd.CommandTarget = FMC_SDRAM_CMD_TARGET_BANK2;
  HAL_SDRAM_SendCommand(&hsdram2, &cmd, 0xFFFF);

  cmd.CommandMode     = FMC_SDRAM_CMD_AUTOREFRESH_MODE;
  cmd.CommandTarget   = FMC_SDRAM_CMD_TARGET_BANK2;
  cmd.AutoRefreshNumber = 8;
  HAL_SDRAM_SendCommand(&hsdram2, &cmd, 0xFFFF);

  cmd.CommandMode  = FMC_SDRAM_CMD_LOAD_MODE;
  cmd.CommandTarget = FMC_SDRAM_CMD_TARGET_BANK2;
  cmd.AutoRefreshNumber = 1;
  cmd.ModeRegisterDefinition = 0x0230;
  HAL_SDRAM_SendCommand(&hsdram2, &cmd, 0xFFFF);

  HAL_SDRAM_ProgramRefreshRate(&hsdram2, 824);

  /* Clear the framebuffers so LTDC displays black instead of SDRAM power-up
     garbage from the moment it starts scanning (before LVGL is up). */
  for (int i = 0; i < 2; i++) {
      uint32_t *fb = (uint32_t *)(FB_ADDR1 + i * (800 * 480 * 2));
      for (uint32_t j = 0; j < (800 * 480 * 2) / 4; j++) {
          fb[j] = 0;
      }
      SCB_CleanDCache_by_Addr((uint32_t *)fb, 800 * 480 * 2);
  }
  /* USER CODE END FMC_Init 2 */
}

static void MX_GPIO_Init(void)
{
  GPIO_InitTypeDef GPIO_InitStruct = {0};

  /* GPIO Ports Clock Enable */
  __HAL_RCC_GPIOI_CLK_ENABLE();
  __HAL_RCC_GPIOK_CLK_ENABLE();
  __HAL_RCC_GPIOG_CLK_ENABLE();
  __HAL_RCC_GPIOD_CLK_ENABLE();
  __HAL_RCC_GPIOE_CLK_ENABLE();
  __HAL_RCC_GPIOJ_CLK_ENABLE();
  __HAL_RCC_GPIOA_CLK_ENABLE();
  __HAL_RCC_GPIOH_CLK_ENABLE();
  __HAL_RCC_GPIOC_CLK_ENABLE();
  __HAL_RCC_GPIOF_CLK_ENABLE();
  __HAL_RCC_GPIOB_CLK_ENABLE();

  /*Configure GPIO pin : PG3 (Touch_INT) */
  GPIO_InitStruct.Pin = GPIO_PIN_3;
  GPIO_InitStruct.Mode = GPIO_MODE_INPUT;
  GPIO_InitStruct.Pull = GPIO_NOPULL;
  HAL_GPIO_Init(GPIOG, &GPIO_InitStruct);

  /*Configure GPIO pin : PG7 (Touch_RST) */
  GPIO_InitStruct.Pin = GPIO_PIN_7;
  GPIO_InitStruct.Mode = GPIO_MODE_OUTPUT_PP;
  GPIO_InitStruct.Pull = GPIO_PULLDOWN;
  GPIO_InitStruct.Speed = GPIO_SPEED_FREQ_LOW;
  HAL_GPIO_Init(GPIOG, &GPIO_InitStruct);
  HAL_GPIO_WritePin(GPIOG, GPIO_PIN_7, GPIO_PIN_RESET);

}

/* USER CODE BEGIN 4 */
/* NAND mount can take a long time (or effectively never finish if no NAND is
   fitted), so it runs here instead of blocking the LVGL task. */
void StartMountTask(void *argument)
{
  (void)argument;
  yaffs_mount_nand();
  for (;;)
  {
    osDelay(1000);
  }
}

void vApplicationStackOverflowHook(TaskHandle_t xTask, char *pcTaskName)
{
  /* Attach a debugger here; xTask/pcTaskName identify the offending task. */
  (void)xTask;
  (void)pcTaskName;
  __disable_irq();
  while (1)
  {
  }
}

void vApplicationMallocFailedHook(void)
{
  __disable_irq();
  while (1)
  {
  }
}
/* USER CODE END 4 */

void StartDefaultTask(void *argument)
{
  /* USER CODE BEGIN 5 */
  /* LVGL must be initialized after the kernel is running: the LTDC driver
     creates CMSIS-RTOS2 sync objects. The tick callback must be registered
     AFTER lv_init(): lv_init() zeroes LVGL's global state, which would
     otherwise wipe the callback and freeze LVGL's tick (no timer would ever
     fire again). */
  lv_init();
  lv_tick_set_cb(HAL_GetTick);
  lv_st_ltdc_create_direct((void *)FB_ADDR1, (void *)FB_ADDR2, 0);
  Touch_Init();
  Touch_CreateLvglIndev();
  lv_demo_widgets();

  /* Render the first frame, then turn the backlight on so the panel only
     ever lights up with valid content. */
  lv_timer_handler();
  HAL_GPIO_WritePin(GPIOD, GPIO_PIN_13, GPIO_PIN_SET);

  /* Infinite loop */
  for(;;)
  {
    lv_timer_handler();
    osDelay(5);
  }
  /* USER CODE END 5 */
}

 /* MPU Configuration */

void MPU_Config(void)
{
  MPU_Region_InitTypeDef MPU_InitStruct = {0};

  /* Disables the MPU */
  HAL_MPU_Disable();

  /** Initializes and configures the Region and the memory to be protected
  */
  MPU_InitStruct.Enable = MPU_REGION_ENABLE;
  MPU_InitStruct.Number = MPU_REGION_NUMBER0;
  MPU_InitStruct.BaseAddress = 0x0;
  MPU_InitStruct.Size = MPU_REGION_SIZE_4GB;
  MPU_InitStruct.SubRegionDisable = 0x87;
  MPU_InitStruct.TypeExtField = MPU_TEX_LEVEL0;
  MPU_InitStruct.AccessPermission = MPU_REGION_NO_ACCESS;
  MPU_InitStruct.DisableExec = MPU_INSTRUCTION_ACCESS_DISABLE;
  MPU_InitStruct.IsShareable = MPU_ACCESS_SHAREABLE;
  MPU_InitStruct.IsCacheable = MPU_ACCESS_NOT_CACHEABLE;
  MPU_InitStruct.IsBufferable = MPU_ACCESS_NOT_BUFFERABLE;

  HAL_MPU_ConfigRegion(&MPU_InitStruct);

  /** Initializes and configures the Region and the memory to be protected
  */
  MPU_InitStruct.Number = MPU_REGION_NUMBER1;
  MPU_InitStruct.BaseAddress = 0xD0000000;
  MPU_InitStruct.Size = MPU_REGION_SIZE_64MB;
  MPU_InitStruct.SubRegionDisable = 0x0;
  MPU_InitStruct.TypeExtField = MPU_TEX_LEVEL1;
  MPU_InitStruct.AccessPermission = MPU_REGION_PRIV_RW;
  MPU_InitStruct.DisableExec = MPU_INSTRUCTION_ACCESS_ENABLE;
  MPU_InitStruct.IsShareable = MPU_ACCESS_NOT_SHAREABLE;
  MPU_InitStruct.IsCacheable = MPU_ACCESS_CACHEABLE;
  MPU_InitStruct.IsBufferable = MPU_ACCESS_BUFFERABLE;

  HAL_MPU_ConfigRegion(&MPU_InitStruct);

  /* Enables the MPU */
  HAL_MPU_Enable(MPU_PRIVILEGED_DEFAULT);

}

void HAL_TIM_PeriodElapsedCallback(TIM_HandleTypeDef *htim)
{
  if (htim->Instance == TIM5)
  {
    HAL_IncTick();
  }
}

void Error_Handler(void)
{
  __disable_irq();
  while (1)
  {
  }
}
